# STM32H503 register map
File version: 1.5
CPU: CM33 r0p0, little endian, MPU, FPU, 4 interrupt priority bits
Registers are 32-bit, read-write, reset 0x0 unless marked. A register's access mark holds for its fields unless they carry their own. Offsets are from the block's base; [hi:lo] are bit positions; lines under a group give offsets from that group; {n}, {i} and the like mark numbered series; 'fields as' and 'values as' point back to an identical list.

## ADC1 — Analog to digital converter
Base 0x42028000
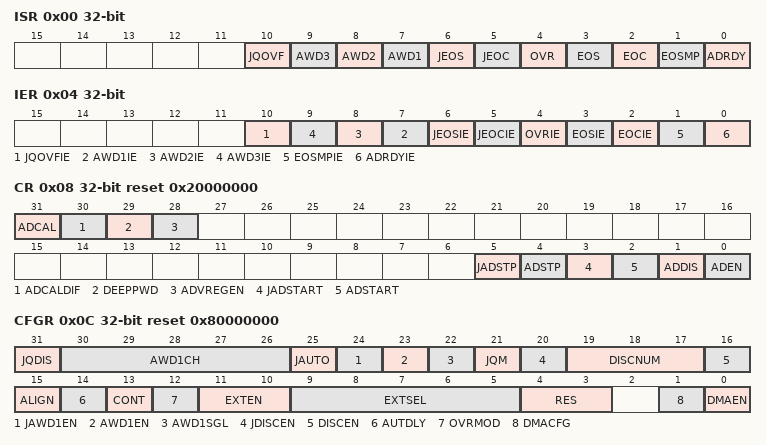
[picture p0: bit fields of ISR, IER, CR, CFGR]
0x00 ISR — ADC interrupt and status register
  [10] JQOVF write-1-clears — Injected context queue overflow This bit is set by hardware when an Overflow of the Injected Queue of Context occurs. It is cleared by software writing 1 to it. Refer to for more information.
    on read: 0=NoOverflow (No injected context queue overflow has occurred); 1=Overflow (Injected context queue overflow has occurred) | on write: 1=Clear injected context queue overflow flag
  [n+6] AWD{n} (n=1..3) write-1-clears — Analog watchdog {n} flag
    on read: 0=NoEvent (No analog watchdog event occurred); 1=Event (Analog watchdog event occurred) | on write: 1=Clear analog watchdog event occurred flag
  [6] JEOS write-1-clears — Injected channel end of sequence flag This bit is set by hardware at the end of the conversions of all injected channels in the group. It is cleared by software writing 1 to it.
    on read: 0=NotComplete (Injected sequence is not complete); 1=Complete (Injected sequence complete) | on write: 1=Clear Injected sequence complete flag
  [5] JEOC write-1-clears — Injected channel end of conversion flag This bit is set by hardware at the end of each injected conversion of a channel when a new data is available in the corresponding ADC_JDRy register. It is cleared by software writing 1 to it or by reading the corresponding ADC_JDRy register
    on read: 0=NotComplete (Injected conversion is not complete); 1=Complete (Injected conversion complete) | on write: 1=Clear injected conversion complete flag
  [4] OVR write-1-clears — ADC overrun This bit is set by hardware when an overrun occurs on a regular channel, meaning that a new conversion has completed while the EOC flag was already set. It is cleared by software writing 1 to it.
    on read: 0=No overrun occurred; 1=Overrun occurred | on write: 1=Clear overrun occurred flag
  [3] EOS write-1-clears — End of regular sequence flag This bit is set by hardware at the end of the conversions of a regular sequence of channels. It is cleared by software writing 1 to it.
    on read: 0=NotComplete (Regular sequence is not complete); 1=Complete (Regular sequence complete) | on write: 1=Clear regular sequence complete flag
  [2] EOC write-1-clears — End of conversion flag This bit is set by hardware at the end of each regular conversion of a channel when a new data is available in the ADC_DR register. It is cleared by software writing 1 to it or by reading the ADC_DR register
    on read: 0=NotComplete (Regular conversion is not complete); 1=Complete (Regular conversion complete) | on write: 1=Clear regular conversion complete flag
  [1] EOSMP write-1-clears — End of sampling flag This bit is set by hardware during the conversion of any channel (only for regular channels), at the end of the sampling phase.
    on read: 0=NotEnded (End of sampling phase no yet reached); 1=Ended (End of sampling phase reached) | on write: 1=Clear end of sampling phase reached flag
  [0] ADRDY write-1-clears — ADC ready This bit is set by hardware after the ADC has been enabled (ADEN = 1) and when the ADC reaches a state where it is ready to accept conversion requests. It is cleared by software writing 1 to it.
    on read: 0=NotReady (ADC is not ready to start conversion); 1=Ready (ADC is ready to start conversion) | on write: 1=Clear ADC is ready to start conversion flag
0x04 IER — ADC interrupt enable register
  [10] JQOVFIE — Injected context queue overflow interrupt enable This bit is set and cleared by software to enable/disable the Injected Context Queue Overflow interrupt. Note: The software is allowed to write this bit only when JADSTART = 0 (which ensures that no injected conversion is ongoing).
    0=Disabled (Injected context queue overflow interrupt disabled); 1=Enabled (Injected context queue overflow interrupt enabled)
  [n+6] AWD{n}IE (n=1..3) — Analog watchdog {n} interrupt enable
    0=Disabled (Analog watchdog interrupt disabled); 1=Enabled (Analog watchdog interrupt enabled)
  [6] JEOSIE — End of injected sequence of conversions interrupt enable This bit is set and cleared by software to enable/disable the end of injected sequence of conversions interrupt. Note: The software is allowed to write this bit only when JADSTART = 0 (which ensures that no injected conversion is ongoing).
    0=Disabled (End of injected sequence interrupt disabled); 1=Enabled (End of injected sequence interrupt enabled)
  [5] JEOCIE — End of injected conversion interrupt enable This bit is set and cleared by software to enable/disable the end of an injected conversion interrupt. Note: The software is allowed to write this bit only when JADSTART = 0 (which ensures that no injected conversion is ongoing).
    0=Disabled (End of injected conversion interrupt disabled); 1=Enabled (End of injected conversion interrupt enabled)
  [4] OVRIE — Overrun interrupt enable This bit is set and cleared by software to enable/disable the Overrun interrupt of a regular conversion. Note: The software is allowed to write this bit only when ADSTART = 0 (which ensures that no regular conversion is ongoing).
    0=Disabled (Overrun interrupt disabled); 1=Enabled (Overrun interrupt enabled)
  [3] EOSIE — End of regular sequence of conversions interrupt enable This bit is set and cleared by software to enable/disable the end of regular sequence of conversions interrupt. Note: The software is allowed to write this bit only when ADSTART = 0 (which ensures that no regular conversion is ongoing).
    0=Disabled (End of regular sequence interrupt disabled); 1=Enabled (End of regular sequence interrupt enabled)
  [2] EOCIE — End of regular conversion interrupt enable This bit is set and cleared by software to enable/disable the end of a regular conversion interrupt. Note: The software is allowed to write this bit only when ADSTART = 0 (which ensures that no regular conversion is ongoing).
    0=Disabled (End of regular conversion interrupt disabled); 1=Enabled (End of regular conversion interrupt enabled)
  [1] EOSMPIE — End of sampling flag interrupt enable for regular conversions This bit is set and cleared by software to enable/disable the end of the sampling phase interrupt for regular conversions. Note: The software is allowed to write this bit only when ADSTART = 0 (which ensures that no regular conversion is ongoing).
    0=Disabled (End of regular conversion sampling phase interrupt disabled); 1=Enabled (End of regular conversion sampling phase interrupt enabled)
  [0] ADRDYIE — ADC ready interrupt enable This bit is set and cleared by software to enable/disable the ADC Ready interrupt. Note: The software is allowed to write this bit only when ADSTART = 0 and JADSTART = 0 (which ensures that no conversion is ongoing).
    0=Disabled (ADC ready interrupt disabled); 1=Enabled (ADC ready interrupt enabled)
0x08 CR reset 0x20000000 — ADC control register
  [31] ADCAL write-1-sets — ADC calibration This bit is set by software to start the calibration of the ADC. Program first the bit ADCALDIF to determine if this calibration applies for Single-ended or Differential inputs mode. It is cleared by hardware after calibration is complete. Note: The software is allowed to launch a calibration by setting ADCAL only when ADEN = 0. The software is allowed to update the calibration factor by writing ADC_CALFACT only when ADEN = 1 and ADSTART = 0 and JADSTART = 0 (ADC enabled and no conversion is ongoing)
    on read: 0=NotCalibrating (ADC calibration either not yet performed or completed); 1=Calibrating (ADC calibration in progress) | on write: 1=StartCalibration (Start the ADC calibration sequence)
  [30] ADCALDIF — Differential mode for calibration This bit is set and cleared by software to configure the Single-ended or Differential inputs mode for the calibration. Note: The software is allowed to write this bit only when the ADC is disabled and is not calibrating (ADCAL = 0, JADSTART = 0, JADSTP = 0, ADSTART = 0, ADSTP = 0, ADDIS = 0 and ADEN = 0).
    0=SingleEnded (Calibration for single-ended mode); 1=Differential (Calibration for differential mode)
  [29] DEEPPWD — Deep-power-down enable This bit is set and cleared by software to put the ADC in Deep-power-down mode. Note: The software is allowed to write this bit only when the ADC is disabled (ADCAL = 0, JADSTART = 0, JADSTP = 0, ADSTART = 0, ADSTP = 0, ADDIS = 0 and ADEN = 0).
    0=NotDeepPowerDown (ADC not in Deep-power down); 1=DeepPowerDown (ADC in Deep-power-down (default reset state))
  [28] ADVREGEN — ADC voltage regulator enable This bits is set by software to enable the ADC voltage regulator. Before performing any operation such as launching a calibration or enabling the ADC, the ADC voltage regulator must first be enabled and the software must wait for the regulator start-up time. For more details about the ADC voltage regulator enable and disable sequences, refer to (ADVREGEN). The software can program this bit field only when the ADC is disabled (ADCAL = 0, JADSTART = 0, ADSTART = 0, ADSTP = 0, ADDIS = 0 and ADEN = 0).
    0=Disabled (ADC Voltage regulator disabled); 1=Enabled (ADC Voltage regulator enabled)
  [5] JADSTP write-1-sets — ADC stop of injected conversion command This bit is set by software to stop and discard an ongoing injected conversion (JADSTP Command). It is cleared by hardware when the conversion is effectively discarded and the ADC injected sequence and triggers can be re-configured. The ADC is then ready to accept a new start of injected conversions (JADSTART command). Note: The software is allowed to set JADSTP only when JADSTART = 1 and ADDIS = 0 (ADC is enabled and eventually converting an injected conversion and there is no pending request to disable the ADC) In Auto-injection mode (JAUTO = 1), setting ADSTP bit aborts both regular and injected conversions (do not use JADSTP)
    on read: 0=NotStopping (No stop command active); 1=Stopping (ADC stopping conversion) | on write: 1=StopConversion (Stop the active conversion)
  [4] ADSTP write-1-sets — ADC stop of regular conversion command This bit is set by software to stop and discard an ongoing regular conversion (ADSTP Command). It is cleared by hardware when the conversion is effectively discarded and the ADC regular sequence and triggers can be re-configured. The ADC is then ready to accept a new start of regular conversions (ADSTART command). Note: The software is allowed to set ADSTP only when ADSTART = 1 and ADDIS = 0 (ADC is enabled and eventually converting a regular conversion and there is no pending request to disable the ADC). In auto-injection mode (JAUTO = 1), setting ADSTP bit aborts both regular and injected conversions (do not use JADSTP).
    values as JADSTP
  [3] JADSTART write-1-sets — ADC start of injected conversion This bit is set by software to start ADC conversion of injected channels. Depending on the configuration bits JEXTEN, a conversion immediately starts (software trigger configuration) or once an injected hardware trigger event occurs (hardware trigger configuration). It is cleared by hardware: in Single conversion mode when software trigger is selected (JEXTSEL = 0x0): at the assertion of the End of Injected Conversion Sequence (JEOS) flag. in all cases: after the execution of the JADSTP command, at the same time that JADSTP is cleared by hardware. Note: The software is allowed to set JADSTART only when ADEN = 1 and ADDIS = 0 (ADC is enabled and there is no pending request to disable the ADC). In auto-injection mode (JAUTO = 1), regular and auto-injected conversions are started by setting bit ADSTART (JADSTART must be kept cleared)
    on read: 0=NotActive (No conversion ongoing); 1=Active (ADC operating and may be converting) | on write: 1=StartConversion (Start the ADC conversion (may be delayed for hardware triggers))
  [2] ADSTART write-1-sets — ADC start of regular conversion This bit is set by software to start ADC conversion of regular channels. Depending on the configuration bits EXTEN, a conversion immediately starts (software trigger configuration) or once a regular hardware trigger event occurs (hardware trigger configuration). It is cleared by hardware: in Single conversion mode when software trigger is selected (EXTSEL = 0x0): at the assertion of the End of Regular Conversion Sequence (EOS) flag. in all cases: after the execution of the ADSTP command, at the same time that ADSTP is cleared by hardware. Note: The software is allowed to set ADSTART only when ADEN = 1 and ADDIS = 0 (ADC is enabled and there is no pending request to disable the ADC) In auto-injection mode (JAUTO = 1), regular and auto-injected conversions are started by setting bit ADSTART (JADSTART must be kept cleared)
    values as JADSTART
  [1] ADDIS write-1-sets — ADC disable command This bit is set by software to disable the ADC (ADDIS command) and put it into power-down state (OFF state). It is cleared by hardware once the ADC is effectively disabled (ADEN is also cleared by hardware at this time). Note: The software is allowed to set ADDIS only when ADEN = 1 and both ADSTART = 0 and JADSTART = 0 (which ensures that no conversion is ongoing)
    on read: 0=NotDisabling (No disable command active); 1=Disabling (ADC disabling) | on write: 1=Disable the ADC
  [0] ADEN write-1-sets — ADC enable control This bit is set by software to enable the ADC. The ADC is effectively ready to operate once the flag ADRDY has been set. It is cleared by hardware when the ADC is disabled, after the execution of the ADDIS command. Note: The software is allowed to set ADEN only when all bits of ADC_CR registers are 0 (ADCAL = 0, JADSTART = 0, ADSTART = 0, ADSTP = 0, ADDIS = 0 and ADEN = 0) except for bit ADVREGEN which must be 1 (and the software must have wait for the startup time of the voltage regulator)
    on read: 0=Disabled (ADC disabled); 1=Enabled (ADC enabled) | on write: 1=Enabled (Enable the ADC)
0x0C CFGR access not given reset 0x80000000 — ADC configuration register
  [31] JQDIS rw — Injected Queue disable These bits are set and cleared by software to disable the Injected Queue mechanism : Note: The software is allowed to write this bit only when ADSTART = 0 and JADSTART = 0 (which ensures that no regular nor injected conversion is ongoing). A set or reset of JQDIS bit causes the injected queue to be flushed and the JSQR register is cleared.
  [30:26] AWD1CH rw range 0..19 — Analog watchdog 1 channel selection These bits are set and cleared by software. They select the input channel to be guarded by the analog watchdog. ..... others: reserved, must not be used Note: Some channels are not connected physically. Keep the corresponding AWD1CH[4:0] setting to the reset value. The channel selected by AWD1CH must be also selected into the SQRi or JSQRi registers. The software is allowed to write these bits only when ADSTART = 0 and JADSTART = 0 (which ensures that no conversion is ongoing).
  [25] JAUTO rw — Automatic injected group conversion This bit is set and cleared by software to enable/disable automatic injected group conversion after regular group conversion. Note: The software is allowed to write this bit only when ADSTART = 0 and JADSTART = 0 (which ensures that no regular nor injected conversion is ongoing).
    0=Disabled (Automatic injected group conversion disabled); 1=Enabled (Automatic injected group conversion enabled)
  [24] JAWD1EN rw — Analog watchdog 1 enable on injected channels This bit is set and cleared by software Note: The software is allowed to write this bit only when JADSTART = 0 (which ensures that no injected conversion is ongoing).
    0=Disabled (Analog watchdog 1 disabled on injected channels); 1=Enabled (Analog watchdog 1 enabled on injected channels)
  [23] AWD1EN rw — Analog watchdog 1 enable on regular channels This bit is set and cleared by software Note: The software is allowed to write this bit only when ADSTART = 0 (which ensures that no regular conversion is ongoing).
    0=Disabled (Analog watchdog 1 disabled on regular channels); 1=Enabled (Analog watchdog 1 enabled on regular channels)
  [22] AWD1SGL rw — Enable the watchdog 1 on a single channel or on all channels This bit is set and cleared by software to enable the analog watchdog on the channel identified by the AWD1CH[4:0] bits or on all the channels Note: The software is allowed to write these bits only when ADSTART = 0 and JADSTART = 0 (which ensures that no conversion is ongoing).
    0=All (Analog watchdog 1 enabled on all channels); 1=Single (Analog watchdog 1 enabled on single channel selected in AWD1CH)
  [21] JQM rw — JSQR queue mode This bit is set and cleared by software. It defines how an empty Queue is managed. Refer to for more information. Note: The software is allowed to write this bit only when JADSTART = 0 (which ensures that no injected conversion is ongoing).
    0=Mode0 (JSQR Mode 0: Queue maintains the last written configuration into JSQR); 1=Mode1 (JSQR Mode 1: An empty queue disables software and hardware triggers of the injected sequence)
  [20] JDISCEN rw — Discontinuous mode on injected channels This bit is set and cleared by software to enable/disable Discontinuous mode on the injected channels of a group. Note: The software is allowed to write this bit only when JADSTART = 0 (which ensures that no injected conversion is ongoing). It is not possible to use both auto-injected mode and Discontinuous mode simultaneously: the bits DISCEN and JDISCEN must be kept cleared by software when JAUTO is set.
    0=Disabled (Discontinuous mode on injected channels disabled); 1=Enabled (Discontinuous mode on injected channels enabled)
  [19:17] DISCNUM rw — Discontinuous mode channel count These bits are written by software to define the number of regular channels to be converted in Discontinuous mode, after receiving an external trigger. ... Note: The software is allowed to write these bits only when ADSTART = 0 (which ensures that no regular conversion is ongoing).
  [16] DISCEN rw — Discontinuous mode for regular channels This bit is set and cleared by software to enable/disable Discontinuous mode for regular channels. Note: It is not possible to have both Discontinuous mode and Continuous mode enabled: it is forbidden to set both DISCEN = 1 and CONT = 1. It is not possible to use both auto-injected mode and Discontinuous mode simultaneously: the bits DISCEN and JDISCEN must be kept cleared by software when JAUTO is set. The software is allowed to write this bit only when ADSTART = 0 (which ensures that no regular conversion is ongoing).
    0=Disabled (Discontinuous mode on regular channels disabled); 1=Enabled (Discontinuous mode on regular channels enabled)
  [15] ALIGN rw — Data alignment This bit is set and cleared by software to select right or left alignment. Refer to register, data alignment and offset (ADC_DR, OFFSET, OFFSET_CH, ALIGN). Note: The software is allowed to write this bit only when ADSTART = 0 and JADSTART = 0 (which ensures that no conversion is ongoing).
    0=Right alignment; 1=Left alignment
  [14] AUTDLY rw — Delayed conversion mode This bit is set and cleared by software to enable/disable the Auto Delayed Conversion mode.. Note: The software is allowed to write this bit only when ADSTART = 0 and JADSTART = 0 (which ensures that no conversion is ongoing).
    0=Off (Auto delayed conversion mode off); 1=On (Auto delayed conversion mode on)
  [13] CONT rw — Single / Continuous conversion mode for regular conversions This bit is set and cleared by software. If it is set, regular conversion takes place continuously until it is cleared. Note: It is not possible to have both Discontinuous mode and Continuous mode enabled: it is forbidden to set both DISCEN = 1 and CONT = 1. The software is allowed to write this bit only when ADSTART = 0 (which ensures that no regular conversion is ongoing).
    0=Single conversion mode; 1=Continuous conversion mode
  [12] OVRMOD rw — Overrun mode This bit is set and cleared by software and configure the way data overrun is managed. Note: The software is allowed to write this bit only when ADSTART = 0 (which ensures that no regular conversion is ongoing).
    0=Preserve DR register when an overrun is detected; 1=Overwrite DR register when an overrun is detected
  [11:10] EXTEN rw — External trigger enable and polarity selection for regular channels These bits are set and cleared by software to select the external trigger polarity and enable the trigger of a regular group. Note: The software is allowed to write these bits only when ADSTART = 0 (which ensures that no regular conversion is ongoing).
    0=Disabled (Trigger detection disabled); 1=RisingEdge (Trigger detection on the rising edge); 2=FallingEdge (Trigger detection on the falling edge); 3=BothEdges (Trigger detection on both the rising and falling edges)
  [9:5] EXTSEL — External trigger selection for regular group These bits select the external event used to trigger the start of conversion of a regular group: ... Note: The software is allowed to write these bits only when ADSTART = 0 (which ensures that no regular conversion is ongoing).
    0=TIM1_CC1 (Timer 1 CC1 event); 1=TIM1_CC2 (Timer 1 CC2 event); 2=TIM1_CC3 (Timer 1 CC3 event); 3=TIM2_CC2 (Timer 2 CC2 event); 4=TIM3_TRGO (Timer 3 TRGO event); 6=EXTI11 (EXTI line 11); 9=TIM1_TRGO (Timer 1 TRGO event); 10=TIM1_TRGO2 (Timer 1 TRGO2 event); 11=TIM2_TRGO (Timer 2 TRGO event); 13=TIM6_TRGO (Timer 6 TRGO event); 14=TIM15_TRGO (Timer 15 TRGO event); 15=TIM3_CC4 (Timer 3 CC4 event)
  [4:3] RES rw — Data resolution These bits are written by software to select the resolution of the conversion. Note: The software is allowed to write these bits only when ADSTART = 0 and JADSTART = 0 (which ensures that no conversion is ongoing).
    0=Bits12 (12-bit); 1=Bits10 (10-bit); 2=Bits8 (8-bit); 3=Bits6 (6-bit)
  [1] DMACFG rw — Direct memory access configuration This bit is set and cleared by software to select between two DMA modes of operation and is effective only when DMAEN = 1. For more details, refer to Note: The software is allowed to write this bit only when ADSTART = 0 and JADSTART = 0 (which ensures that no conversion is ongoing).
    0=OneShot (DMA One Shot mode selected); 1=Circular (DMA Circular mode selected)
  [0] DMAEN rw — Direct memory access enable This bit is set and cleared by software to enable the generation of DMA requests. This allows to use the DMA to manage automatically the converted data. For more details, refer to conversions using the DMA. Note: The software is allowed to write this bit only when ADSTART = 0 and JADSTART = 0 (which ensures that no conversion is ongoing).
    0=Disabled (DMA disabled); 1=Enabled (DMA enabled)
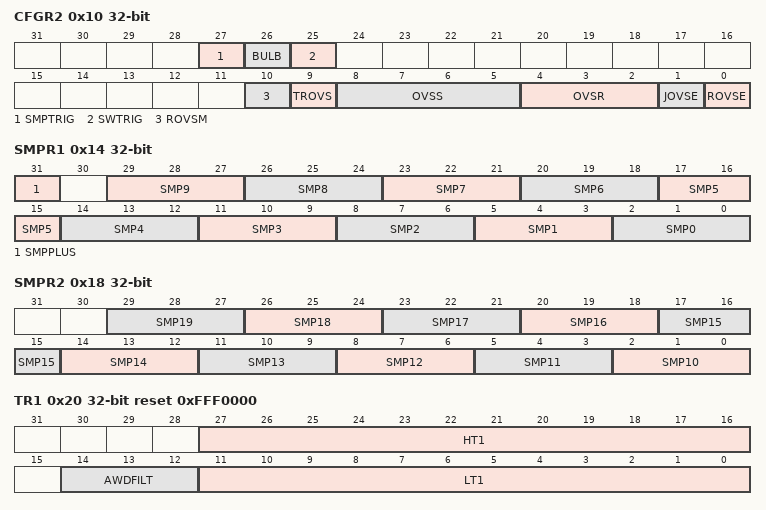
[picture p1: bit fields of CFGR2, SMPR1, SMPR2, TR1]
0x10 CFGR2 — ADC configuration register 2
  [27] SMPTRIG — Sampling time control trigger mode This bit is set and cleared by software to enable the sampling time control trigger mode. The sampling time starts on the trigger rising edge, and the conversion on the trigger falling edge. EXTEN bit should be set to 01. BULB bit must not be set when the SMPTRIG bit is set. When EXTEN bit is set to 00, set SWTRIG to start the sampling and clear SWTRIG bit to start the conversion. Note: The software is allowed to write this bit only when ADSTART = 0 (which ensures that no conversion is ongoing).
    0=Disabled (Sampling time control trigger mode disabled); 1=Enabled (Sampling time control trigger mode enabled)
  [26] BULB — Bulb sampling mode This bit is set and cleared by software to enable the bulb sampling mode. SAMPTRIG bit must not be set when the BULB bit is set. The very first ADC conversion is performed with the sampling time specified in SMPx bits. Note: The software is allowed to write this bit only when ADSTART = 0 (which ensures that no conversion is ongoing).
    0=Disabled (Bulb sampling mode disabled); 1=Enabled (Bulb sampling mode enabled. The sampling period starts just after the previous end of conversion)
  [25] SWTRIG — Software trigger bit for sampling time control trigger mode This bit is set and cleared by software to enable the bulb sampling mode. Note: The software is allowed to write this bit only when ADSTART = 0 (which ensures that no conversion is ongoing).
    0=Conversion (Software trigger starts the conversion for sampling time control trigger mode); 1=Sampling (Software trigger starts the sampling for sampling time control trigger mode)
  [10] ROVSM — Regular Oversampling mode This bit is set and cleared by software to select the regular oversampling mode. Note: The software is allowed to write this bit only when ADSTART = 0 (which ensures that no conversion is ongoing).
    0=ContinuedMode (When injected conversions are triggered, the oversampling is temporary stopped and continued after the injection sequence (oversampling buffer is maintained during injected sequence)); 1=ResumedMode (When injected conversions are triggered, the current oversampling is aborted and resumed from start after the injection sequence (oversampling buffer is zeroed by injected sequence start))
  [9] TROVS — Triggered Regular Oversampling This bit is set and cleared by software to enable triggered oversampling Note: The software is allowed to write this bit only when ADSTART = 0 (which ensures that no conversion is ongoing).
    0=All (All oversampled conversions for a channel are done consecutively following a trigger); 1=Single (Each oversampled conversion for a channel needs a new trigger)
  [8:5] OVSS — Oversampling shift This bitfield is set and cleared by software to define the right shifting applied to the raw oversampling result. Other codes reserved Note: The software is allowed to write these bits only when ADSTART = 0 (which ensures that no conversion is ongoing).
    0=NoShift; {v}=Shift{v}Bit (v=1..8)
  [4:2] OVSR — Oversampling ratio This bitfield is set and cleared by software to define the oversampling ratio. Note: The software is allowed to write these bits only when ADSTART = 0 (which ensures that no conversion is ongoing).
    0=Ratio2 (2x); 1=Ratio4 (4x); 2=Ratio8 (8x); 3=Ratio16 (16x); 4=Ratio32 (32x); 5=Ratio64 (64x); 6=Ratio128 (128x); 7=Ratio256 (256x)
  [1] JOVSE — Injected Oversampling Enable This bit is set and cleared by software to enable injected oversampling. Note: The software is allowed to write this bit only when ADSTART = 0 and JADSTART = 0 (which ensures that no conversion is ongoing)
    0=Disabled (Injected Oversampling disabled); 1=Enabled (Injected Oversampling enabled)
  [0] ROVSE — Regular Oversampling Enable This bit is set and cleared by software to enable regular oversampling. Note: The software is allowed to write this bit only when ADSTART = 0 and JADSTART = 0 (which ensures that no conversion is ongoing)
    0=Disabled (Regular Oversampling disabled); 1=Enabled (Regular Oversampling enabled)
0x14 SMPR1 — ADC sample time register 1
  [31] SMPPLUS — Addition of one clock cycle to the sampling time. To make sure no conversion is ongoing, the software is allowed to write this bit only when ADSTART = 0 and JADSTART = 0.
    0=KeepCycles (The sampling time remains set to 2.5 ADC clock cycles remains); 1=Add1Cycle (2.5 ADC clock cycle sampling time becomes 3.5 ADC clock cycles for the ADC_SMPR1 and ADC_SMPR2 registers)
  [3n+2:3n] SMP{n} (n=0..9) — Channel {n} sample time selection
    0=Cycles2_5 (2.5 ADC clock cycles); 1=Cycles6_5 (6.5 ADC clock cycles); 2=Cycles12_5 (12.5 ADC clock cycles); 3=Cycles24_5 (24.5 ADC clock cycles); 4=Cycles47_5 (47.5 ADC clock cycles); 5=Cycles92_5 (92.5 ADC clock cycles); 6=Cycles247_5 (247.5 ADC clock cycles); 7=Cycles640_5 (640.5 ADC clock cycles)
0x18 SMPR2 — ADC sample time register 2
  [3n-28:3n-30] SMP{n} (n=10..19) — Channel {n} sample time selection
    values as SMPR1.SMP0
0x20 TR1 reset 0xFFF0000 — ADC watchdog threshold register 1
  [27:16] HT1 — Analog watchdog 1 higher threshold These bits are written by software to define the higher threshold for the analog watchdog 1. Refer to AWD2CH, AWD3CH, AWD_HTx, AWD_LTx, AWDx) Note: The software is allowed to write these bits only when ADSTART = 0 and JADSTART = 0 (which ensures that no conversion is ongoing).
  [14:12] AWDFILT — Analog watchdog filtering parameter This bit is set and cleared by software. ... Note: The software is allowed to write this bit only when ADSTART = 0 (which ensures that no conversion is ongoing).
  [11:0] LT1 — Analog watchdog 1 lower threshold These bits are written by software to define the lower threshold for the analog watchdog 1. Refer to AWD2CH, AWD3CH, AWD_HTx, AWD_LTx, AWDx) Note: The software is allowed to write these bits only when ADSTART = 0 and JADSTART = 0 (which ensures that no conversion is ongoing).
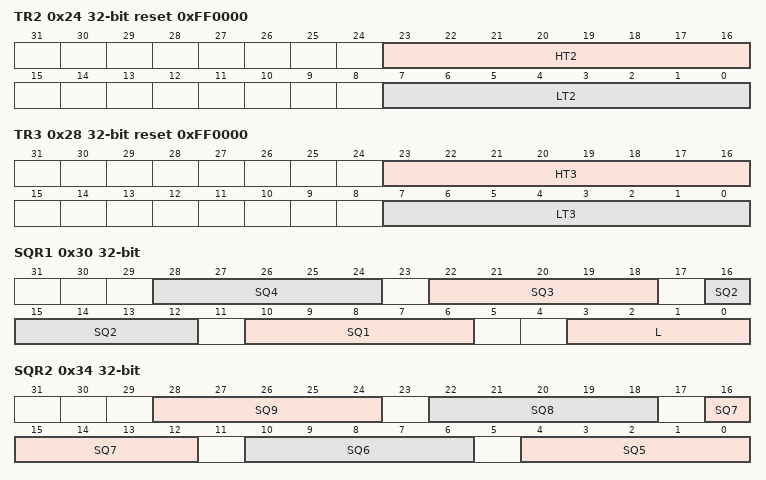
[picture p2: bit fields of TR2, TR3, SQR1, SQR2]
0x24 TR2 reset 0xFF0000 — ADC watchdog threshold register 2
  [23:16] HT2 — Analog watchdog 2 higher threshold These bits are written by software to define the higher threshold for the analog watchdog 2. Refer to AWD2CH, AWD3CH, AWD_HTx, AWD_LTx, AWDx) Note: The software is allowed to write these bits only when ADSTART = 0 and JADSTART = 0 (which ensures that no conversion is ongoing).
  [7:0] LT2 — Analog watchdog 2 lower threshold These bits are written by software to define the lower threshold for the analog watchdog 2. Refer to AWD2CH, AWD3CH, AWD_HTx, AWD_LTx, AWDx) Note: The software is allowed to write these bits only when ADSTART = 0 and JADSTART = 0 (which ensures that no conversion is ongoing).
0x28 TR3 reset 0xFF0000 — ADC watchdog threshold register 3
  [23:16] HT3 — Analog watchdog 3 higher threshold These bits are written by software to define the higher threshold for the analog watchdog 3. Refer to AWD2CH, AWD3CH, AWD_HTx, AWD_LTx, AWDx) Note: The software is allowed to write these bits only when ADSTART = 0 and JADSTART = 0 (which ensures that no conversion is ongoing).
  [7:0] LT3 — Analog watchdog 3 lower threshold These bits are written by software to define the lower threshold for the analog watchdog 3. This watchdog compares the 8-bit of LT3 with the 8 MSB of the converted data. Note: The software is allowed to write these bits only when ADSTART = 0 and JADSTART = 0 (which ensures that no conversion is ongoing).
0x30 SQR1 — ADC regular sequence register 1
  [6n+4:6n] SQ{n} (n=1..4) range 0..19 — {n} conversion in regular sequence
  [3:0] L — Regular channel sequence length These bits are written by software to define the total number of conversions in the regular channel conversion sequence. ... Note: The software is allowed to write these bits only when ADSTART = 0 (which ensures that no regular conversion is ongoing).
0x34 SQR2 — ADC regular sequence register 2
  [6n-26:6n-30] SQ{n} (n=5..9) range 0..19 — {n} conversion in regular sequence
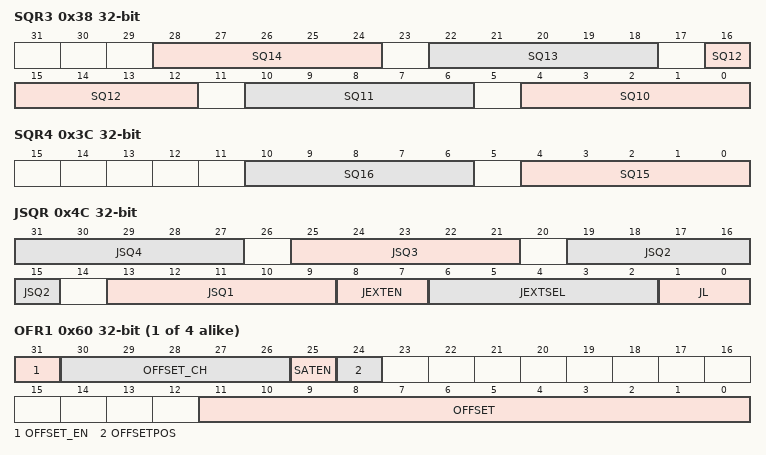
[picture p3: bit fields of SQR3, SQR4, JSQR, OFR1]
0x38 SQR3 — ADC regular sequence register 3
  [6n-56:6n-60] SQ{n} (n=10..14) range 0..19 — {n} conversion in regular sequence
0x3C SQR4 — ADC regular sequence register 4
  [6n-86:6n-90] SQ{n} (n=15..16) range 0..19 — {n} conversion in regular sequence
0x40 DR ro — ADC regular data register
  [15:0] RDATA — Regular data converted These bits are read-only. They contain the conversion result from the last converted regular channel. The data are left- or right-aligned as described in .
0x4C JSQR — ADC injected sequence register
  [6n+7:6n+3] JSQ{n} (n=1..4) range 0..19 — {n} conversion in injected sequence
  [8:7] JEXTEN — External trigger enable and polarity selection for injected channels These bits are set and cleared by software to select the external trigger polarity and enable the trigger of an injected group. Note: The software is allowed to write these bits only when JADSTART = 0 (which ensures that no injected conversion is ongoing). If JQM = 1 and if the Queue of Context becomes empty, the software and hardware triggers of the injected sequence are both internally disabled (refer to Queue of context for injected conversions)
    values as CFGR.EXTEN
  [6:2] JEXTSEL — External Trigger Selection for injected group These bits select the external event used to trigger the start of conversion of an injected group: ... Note: The software is allowed to write these bits only when JADSTART = 0 (which ensures that no injected conversion is ongoing).
    0=TIM1_TRGO (Timer 1 TRGO event); 1=TIM1_CC4 (Timer 1 CC4 event); 2=TIM2_TRGO (Timer 2 TRGO event); 3=TIM2_CC1 (Timer 2 CC1 event); 4=TIM3_CC4 (Timer 3 CC4 event); 6=EXTI15 (EXTI line 15); 8=TIM1_TRGO2 (Timer 1 TRGO2 event); 11=TIM3_CC3 (Timer 3 CC3 event); 12=TIM3_TRGO (Timer 3 TRGO event); 13=TIM3_CC1 (Timer 3 CC1 event); 14=TIM6_TRGO (Timer 6 TRGO event); 15=TIM15_TRGO (Timer 15 TRGO event)
  [1:0] JL — Injected channel sequence length These bits are written by software to define the total number of conversions in the injected channel conversion sequence. Note: The software is allowed to write these bits only when JADSTART = 0 (which ensures that no injected conversion is ongoing).
{0x5C+4i} OFR{i} (i=1..4) — ADC offset {i} register
  [31] OFFSET_EN — Offset y enable This bit is written by software to enable or disable the offset programmed into bits OFFSET[11:0]. Note: The software is allowed to write this bit only when ADSTART = 0 and JADSTART = 0 (which ensures that no conversion is ongoing).
    0=Disabled (This bit is written by software to enable or disable the offset programmed into bits OFFSETy[11:0]); 1=Enabled (This bit is written by software to enable or disable the offset programmed into bits OFFSETy[11:0])
  [30:26] OFFSET_CH — Channel selection for the data offset y These bits are written by software to define the channel to which the offset programmed into bits OFFSET[11:0] applies. Note: The software is allowed to write these bits only when ADSTART = 0 and JADSTART = 0 (which ensures that no conversion is ongoing). Some channels are not connected physically and must not be selected for the data offset y. If OFFSET_EN is set, it is not allowed to select the same channel for different ADC_OFRy registers.
  [25] SATEN — Saturation enable This bit is set and cleared by software to enable the saturation at 0x000 and 0xFFF for the offset function. Note: The software is allowed to write these bits only when ADSTART = 0 and JADSTART = 0 (which ensures that no conversion is ongoing).
  [24] OFFSETPOS — Positive offset This bit is set and cleared by software to enable the positive offset. Note: The software is allowed to write these bits only when ADSTART = 0 and JADSTART = 0 (which ensures that no conversion is ongoing).
  [11:0] OFFSET — Data offset y for the channel programmed into bits OFFSET_CH[4:0] These bits are written by software to define the offset to be subtracted from the raw converted data when converting a channel (can be regular or injected). The channel to which applies the data offset must be programmed in the bits OFFSET_CH[4:0]. The conversion result can be read from in the ADC_DR (regular conversion) or from in the ADC_JDRyi registers (injected conversion). Note: The software is allowed to write these bits only when ADSTART = 0 and JADSTART = 0 (which ensures that no conversion is ongoing). If several offset (OFFSET) point to the same channel, only the offset with the lowest x value is considered for the subtraction. Ex: if OFFSET1_CH[4:0] = 4 and OFFSET2_CH[4:0] = 4, this is OFFSET1[11:0] which is subtracted when converting channel 4.
{0x7C+4i} JDR{i} (i=1..4) ro — ADC injected channel {i} data register
  [15:0] JDATA — Injected data These bits are read-only. They contain the conversion result from injected channel y. The data are left -or right-aligned as described in .
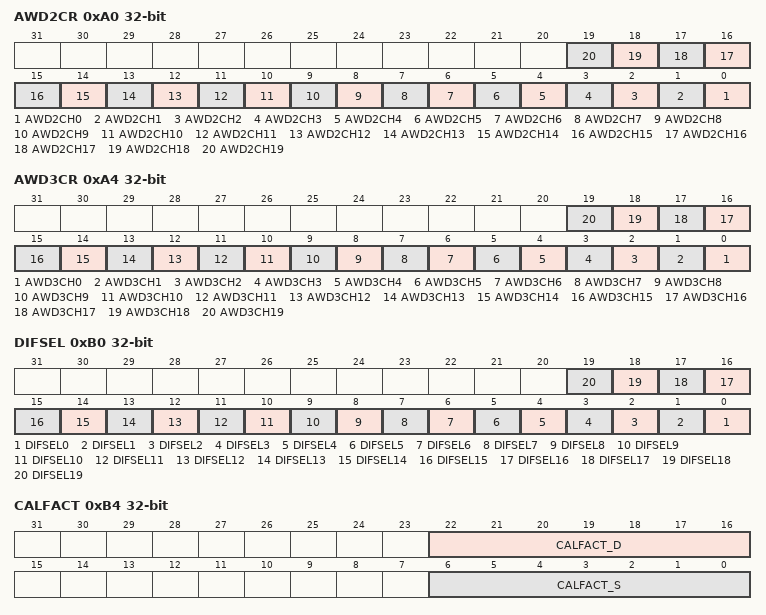
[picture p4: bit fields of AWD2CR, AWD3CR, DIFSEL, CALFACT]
0xA0 AWD2CR access not given — ADC Analog Watchdog 2 Configuration Register
  [n] AWD2CH{n} (n=0..19) — Analog watchdog 2 channel selection These bits are set and cleared by software. They enable and select the input channels to be guarded by the analog watchdog 2. AWD2CH[i] = 0: ADC analog input channel i is not monitored by AWD2 AWD2CH[i] = 1: ADC analog input channel i is monitored by AWD2 When AWD2CH[19:0] = 000..0, the analog Watchdog 2 is disabled Note: The channels selected by AWD2CH must be also selected into the SQRi or JSQRi registers. The software is allowed to write these bits only when ADSTART = 0 and JADSTART = 0 (which ensures that no conversion is ongoing). Some channels are not connected physically and must not be selected for the analog watchdog.
    0=NotMonitored (Input channel not monitored by AWDx); 1=Monitored (Input channel monitored by AWDx)
0xA4 AWD3CR access not given — ADC Analog Watchdog 3 Configuration Register
  [n] AWD3CH{n} (n=0..19) — Analog watchdog 3 channel selection These bits are set and cleared by software. They enable and select the input channels to be guarded by the analog watchdog 3. AWD3CH[i] = 0: ADC analog input channel i is not monitored by AWD3 AWD3CH[i] = 1: ADC analog input channel i is monitored by AWD3 When AWD3CH[19:0] = 000..0, the analog Watchdog 3 is disabled Note: The channels selected by AWD3CH must be also selected into the SQRi or JSQRi registers. The software is allowed to write these bits only when ADSTART = 0 and JADSTART = 0 (which ensures that no conversion is ongoing). Some channels are not connected physically and must not be selected for the analog watchdog.
    values as AWD2CR.AWD2CH0
0xB0 DIFSEL access not given — ADC Differential mode Selection Register
  [n] DIFSEL{n} (n=0..19) — Differential mode for channel {n}
    0=SingleEnded (Input channel is configured in single-ended mode); 1=Differential (Input channel is configured in differential mode)
0xB4 CALFACT — ADC Calibration Factors
  [22:16] CALFACT_D — Calibration Factors in differential mode These bits are written by hardware or by software. Once a differential inputs calibration is complete, they are updated by hardware with the calibration factors. Software can write these bits with a new calibration factor. If the new calibration factor is different from the current one stored into the analog ADC, it is then applied once a new differential calibration is launched. Note: The software is allowed to write these bits only when ADEN = 1, ADSTART = 0 and JADSTART = 0 (ADC is enabled and no calibration is ongoing and no conversion is ongoing).
  [6:0] CALFACT_S — Calibration Factors In Single-ended mode These bits are written by hardware or by software. Once a single-ended inputs calibration is complete, they are updated by hardware with the calibration factors. Software can write these bits with a new calibration factor. If the new calibration factor is different from the current one stored into the analog ADC, it is then applied once a new single-ended calibration is launched. Note: The software is allowed to write these bits only when ADEN = 1, ADSTART = 0 and JADSTART = 0 (ADC is enabled and no calibration is ongoing and no conversion is ongoing).
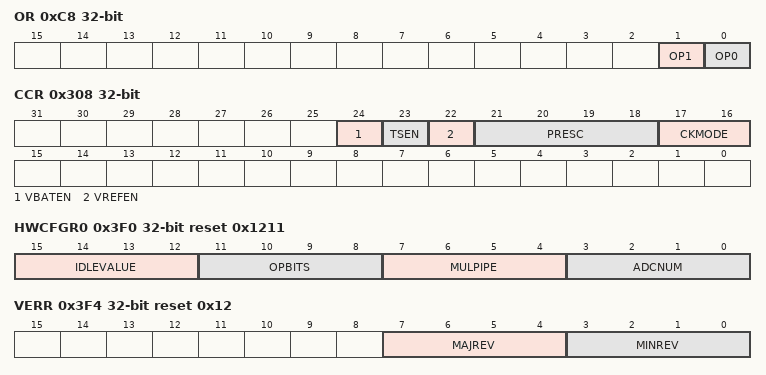
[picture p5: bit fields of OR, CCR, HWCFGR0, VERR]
0xC8 OR — ADC option register
  [1] OP1 — Option bit 1
  [0] OP0 — Option bit 0
0x308 CCR — ADC common control register
  [24] VBATEN — VBAT enable This bit is set and cleared by software to control.
  [23] TSEN — VSENSE enable This bit is set and cleared by software to control VSENSE.
  [22] VREFEN — VREFINT enable This bit is set and cleared by software to enable/disable the VREFINT channel.
  [21:18] PRESC — ADC prescaler These bits are set and cleared by software to select the frequency of the clock to the ADC. The clock is common for all the ADCs. other: reserved Note: The software is allowed to write these bits only when the ADC is disabled (ADCAL = 0, JADSTART = 0, ADSTART = 0, ADSTP = 0, ADDIS = 0 and ADEN = 0). The ADC prescaler value is applied only when CKMODE[1:0] = 0b00.
  [17:16] CKMODE — ADC clock mode These bits are set and cleared by software to define the ADC clock scheme (which is common to both master and slave ADCs): In all synchronous clock modes, there is no jitter in the delay from a timer trigger to the start of a conversion. Note: The software is allowed to write these bits only when the ADCs are disabled (ADCAL = 0, JADSTART = 0, ADSTART = 0, ADSTP = 0, ADDIS = 0 and ADEN = 0).
0x3F0 HWCFGR0 ro reset 0x1211 — ADC hardware configuration register
  [15:12] IDLEVALUE — Idle value for non-selected channels
  [11:8] OPBITS — Number of option bits 0002: 2 option bits implemented in the ADC option register (ADC_OR) at address offset 0xC8
  [7:4] MULPIPE — Number of pipeline stages
  [3:0] ADCNUM — Number of ADCs implemented
0x3F4 VERR ro reset 0x12 — ADC version register
  [7:4] MAJREV — Major revision These bits returns the ADC IP major revision
  [3:0] MINREV — Minor revision These bits returns the ADC IP minor revision 0002: Major revision = X.2
0x3F8 IPDR ro reset 0x110006 — ADC identification register
  [31:0] ID — Peripheral identifier These bits returns the ADC identifier. ID[31:0] = 0x0011 0006: c7amba_aditf5_90_v1
0x3FC SIDR ro reset 0xA3C5DD01 — ADC size identification register
  [31:0] SID — Size Identification SID[31:8]: fixed code that characterizes the ADC_SIDR register. This field is always read at 0xA3C5DD. SID[7:0]: read-only numeric field that returns the address offset (in Kbytes) of the identification registers from the IP base address:
